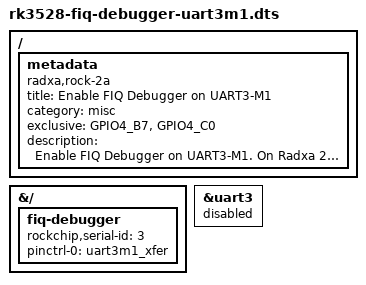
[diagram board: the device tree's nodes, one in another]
/dts-v1/;
/plugin/;

/ {
	metadata {
		title = "Enable FIQ Debugger on UART3-M1";
		compatible = "radxa,rock-2a";
		category = "misc";
		exclusive = "GPIO4_B7", "GPIO4_C0";
		description = "Enable FIQ Debugger on UART3-M1.
On Radxa 2A this is RX pin 11 and TX pin 13.";
	};
};

&{/} {
	fiq-debugger {
		status = "okay";
		rockchip,serial-id = <3>;
		pinctrl-names = "default";
		pinctrl-0 = <&uart3m1_xfer>;
	};
};

&uart3 {
	status = "disabled";
};
